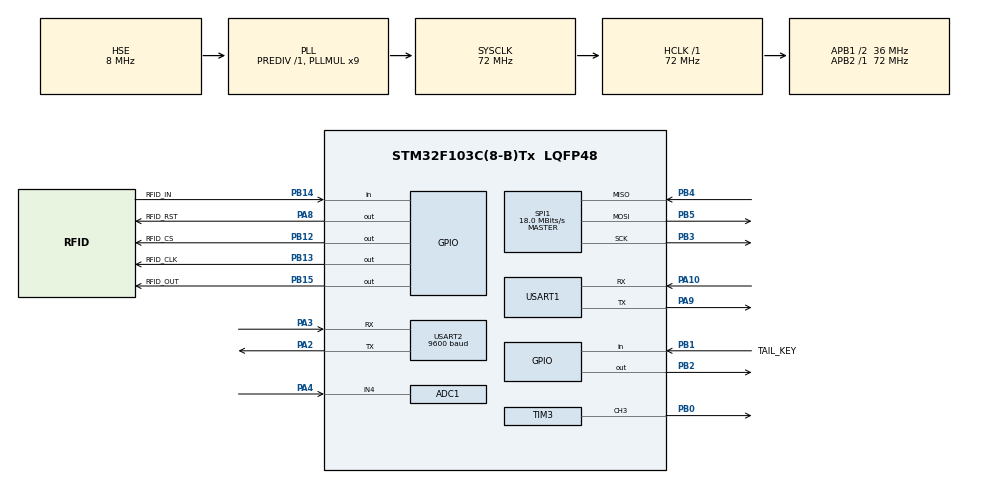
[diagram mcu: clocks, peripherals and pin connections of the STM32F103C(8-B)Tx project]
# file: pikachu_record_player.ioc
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ADC1.Channel-0\#ChannelRegularConversion=ADC_CHANNEL_4
ADC1.ContinuousConvMode=ENABLE
ADC1.NbrOfConversionFlag=1
ADC1.Rank-0\#ChannelRegularConversion=1
ADC1.SamplingTime-0\#ChannelRegularConversion=ADC_SAMPLETIME_239CYCLES_5
ADC1.master=1
Dma.ADC1.4.Direction=DMA_PERIPH_TO_MEMORY
Dma.ADC1.4.Instance=DMA1_Channel1
Dma.ADC1.4.MemDataAlignment=DMA_MDATAALIGN_HALFWORD
Dma.ADC1.4.MemInc=DMA_MINC_ENABLE
Dma.ADC1.4.Mode=DMA_CIRCULAR
Dma.ADC1.4.PeriphDataAlignment=DMA_PDATAALIGN_HALFWORD
Dma.ADC1.4.PeriphInc=DMA_PINC_DISABLE
Dma.ADC1.4.Priority=DMA_PRIORITY_LOW
Dma.Request0=USART1_RX
Dma.Request1=USART1_TX
Dma.Request2=USART2_RX
Dma.Request3=USART2_TX
Dma.Request4=ADC1
Dma.USART1_RX.0.Direction=DMA_PERIPH_TO_MEMORY
Dma.USART1_RX.0.Instance=DMA1_Channel5
Dma.USART1_RX.0.MemDataAlignment=DMA_MDATAALIGN_BYTE
Dma.USART1_RX.0.MemInc=DMA_MINC_ENABLE
Dma.USART1_RX.0.Mode=DMA_NORMAL
Dma.USART1_RX.0.PeriphDataAlignment=DMA_PDATAALIGN_BYTE
Dma.USART1_RX.0.PeriphInc=DMA_PINC_DISABLE
Dma.USART1_RX.0.Priority=DMA_PRIORITY_LOW
Dma.USART1_TX.1.Direction=DMA_MEMORY_TO_PERIPH
Dma.USART1_TX.1.Instance=DMA1_Channel4
Dma.USART1_TX.1.MemDataAlignment=DMA_MDATAALIGN_BYTE
Dma.USART1_TX.1.MemInc=DMA_MINC_ENABLE
Dma.USART1_TX.1.Mode=DMA_NORMAL
Dma.USART1_TX.1.PeriphDataAlignment=DMA_PDATAALIGN_BYTE
Dma.USART1_TX.1.PeriphInc=DMA_PINC_DISABLE
Dma.USART1_TX.1.Priority=DMA_PRIORITY_LOW
Dma.USART2_RX.2.Direction=DMA_PERIPH_TO_MEMORY
Dma.USART2_RX.2.Instance=DMA1_Channel6
Dma.USART2_RX.2.MemDataAlignment=DMA_MDATAALIGN_BYTE
Dma.USART2_RX.2.MemInc=DMA_MINC_ENABLE
Dma.USART2_RX.2.Mode=DMA_NORMAL
Dma.USART2_RX.2.PeriphDataAlignment=DMA_PDATAALIGN_BYTE
Dma.USART2_RX.2.PeriphInc=DMA_PINC_DISABLE
Dma.USART2_RX.2.Priority=DMA_PRIORITY_LOW
Dma.USART2_TX.3.Direction=DMA_MEMORY_TO_PERIPH
Dma.USART2_TX.3.Instance=DMA1_Channel7
Dma.USART2_TX.3.MemDataAlignment=DMA_MDATAALIGN_BYTE
Dma.USART2_TX.3.MemInc=DMA_MINC_ENABLE
Dma.USART2_TX.3.Mode=DMA_NORMAL
Dma.USART2_TX.3.PeriphDataAlignment=DMA_PDATAALIGN_BYTE
Dma.USART2_TX.3.PeriphInc=DMA_PINC_DISABLE
Dma.USART2_TX.3.Priority=DMA_PRIORITY_LOW
FREERTOS.INCLUDE_vTaskDelayUntil=1
FREERTOS.Tasks01=defaultTask,0,128,StartDefaultTask,Default,NULL,Dynamic,NULL,NULL
Mcu.Family=STM32F1
Mcu.Name=STM32F103C(8-B)Tx
Mcu.Package=LQFP48
NVIC.DMA1_Channel1_IRQn=true\:15\:0\:true\:false\:true\:true\:false\:true\:true
NVIC.DMA1_Channel4_IRQn=true\:5\:0\:false\:false\:true\:true\:false\:true\:true
NVIC.DMA1_Channel5_IRQn=true\:5\:0\:false\:false\:true\:true\:false\:true\:true
NVIC.DMA1_Channel6_IRQn=true\:5\:0\:false\:false\:true\:true\:false\:true\:true
NVIC.DMA1_Channel7_IRQn=true\:5\:0\:false\:false\:true\:true\:false\:true\:true
NVIC.PriorityGroup=NVIC_PRIORITYGROUP_4
NVIC.TIM4_IRQn=true\:5\:0\:true\:false\:true\:false\:false\:true\:true
NVIC.TimeBase=TIM4_IRQn
NVIC.TimeBaseIP=TIM4
NVIC.USART1_IRQn=true\:5\:0\:false\:false\:true\:true\:true\:true\:true
NVIC.USART2_IRQn=true\:5\:0\:false\:false\:true\:true\:true\:true\:true
PA10.Mode=Asynchronous
PA10.Signal=USART1_RX
PA13.Mode=Serial_Wire
PA13.Signal=SYS_JTMS-SWDIO
PA14.Mode=Serial_Wire
PA14.Signal=SYS_JTCK-SWCLK
PA2.Mode=Asynchronous
PA2.Signal=USART2_TX
PA3.Mode=Asynchronous
PA3.Signal=USART2_RX
PA4.Signal=ADCx_IN4
PA8.GPIO_Label=RFID_RST
PA8.Signal=GPIO_Output
PA9.Mode=Asynchronous
PA9.Signal=USART1_TX
PB0.Signal=S_TIM3_CH3
PB1.GPIO_Label=TAIL_KEY
PB1.GPIO_PuPd=GPIO_PULLUP
PB1.Signal=GPIO_Input
PB12.GPIO_Label=RFID_CS
PB12.Signal=GPIO_Output
PB13.GPIO_Label=RFID_CLK
PB13.Signal=GPIO_Output
PB14.GPIO_Label=RFID_IN
PB14.Signal=GPIO_Input
PB15.GPIO_Label=RFID_OUT
PB15.Signal=GPIO_Output
PB2.Signal=GPIO_Output
PB3.Mode=Full_Duplex_Master
PB3.Signal=SPI1_SCK
PB4.Mode=Full_Duplex_Master
PB4.Signal=SPI1_MISO
PB5.Mode=Full_Duplex_Master
PB5.Signal=SPI1_MOSI
PD0-OSC_IN.Mode=HSE-External-Oscillator
PD0-OSC_IN.Signal=RCC_OSC_IN
PD1-OSC_OUT.Mode=HSE-External-Oscillator
PD1-OSC_OUT.Signal=RCC_OSC_OUT
ProjectManager.HeapSize=0x200
ProjectManager.StackSize=0x400
ProjectManager.TargetToolchain=MDK-ARM V5.32
RCC.ADCPresc=RCC_ADCPCLK2_DIV6
RCC.AHBFreq_Value=72000000
RCC.APB1CLKDivider=RCC_HCLK_DIV2
RCC.APB1Freq_Value=36000000
RCC.APB1TimFreq_Value=72000000
RCC.APB2Freq_Value=72000000
RCC.APB2TimFreq_Value=72000000
RCC.HCLKFreq_Value=72000000
RCC.PLLMUL=RCC_PLL_MUL9
RCC.PLLSourceVirtual=RCC_PLLSOURCE_HSE
RCC.SYSCLKFreq_VALUE=72000000
RCC.SYSCLKSource=RCC_SYSCLKSOURCE_PLLCLK
RCC.USBFreq_Value=72000000
SH.ADCx_IN4.0=ADC1_IN4,IN4
SH.S_TIM3_CH3.0=TIM3_CH3,PWM Generation3 CH3
SPI1.BaudRatePrescaler=SPI_BAUDRATEPRESCALER_4
SPI1.CalculateBaudRate=18.0 MBits/s
SPI1.Direction=SPI_DIRECTION_2LINES
SPI1.Mode=SPI_MODE_MASTER
SPI1.VirtualType=VM_MASTER
TIM3.Channel-PWM\ Generation3\ CH3=TIM_CHANNEL_3
TIM3.Period=99
TIM3.Prescaler=7199
USART1.VirtualMode=VM_ASYNC
USART2.BaudRate=9600
USART2.VirtualMode=VM_ASYNC
VP_FREERTOS_VS_CMSIS_V1.Mode=CMSIS_V1
VP_SYS_VS_tim4.Mode=TIM4
board=custom

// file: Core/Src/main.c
/* USER CODE BEGIN Header */
/**
  ******************************************************************************
  * @file           : main.c
  * @brief          : Main program body
  ******************************************************************************
  * @attention
  *
  * Copyright (c) 2024 STMicroelectronics.
  * All rights reserved.
  *
  * This software is licensed under terms that can be found in the LICENSE file
  * in the root directory of this software component.
  * If no LICENSE file comes with this software, it is provided AS-IS.
  *
  ******************************************************************************
  */
/* USER CODE END Header */
#include "main.h"
#include "cmsis_os.h"
#include "adc.h"
#include "dma.h"
#include "spi.h"
#include "tim.h"
#include "usart.h"
#include "gpio.h"

void SystemClock_Config(void);
void MX_FREERTOS_Init(void);

int main(void)
{

  /* MCU Configuration--------------------------------------------------------*/

  /* Reset of all peripherals, Initializes the Flash interface and the Systick. */
  HAL_Init();

  /* Configure the system clock */
  SystemClock_Config();

  /* Initialize all configured peripherals */
  MX_GPIO_Init();
  MX_DMA_Init();
  MX_SPI1_Init();
  MX_USART1_UART_Init();
  MX_USART2_UART_Init();
  MX_ADC1_Init();
  MX_TIM3_Init();
  /* USER CODE BEGIN 2 */
	HAL_Delay(2000);
  /* USER CODE END 2 */

  /* Call init function for freertos objects (in freertos.c) */
  MX_FREERTOS_Init();

  /* Start scheduler */
  osKernelStart();

  /* We should never get here as control is now taken by the scheduler */
  /* Infinite loop */
  while (1)
  {

  }
}

void SystemClock_Config(void)
{
  RCC_OscInitTypeDef RCC_OscInitStruct = {0};
  RCC_ClkInitTypeDef RCC_ClkInitStruct = {0};
  RCC_PeriphCLKInitTypeDef PeriphClkInit = {0};

  /** Initializes the RCC Oscillators according to the specified parameters
  * in the RCC_OscInitTypeDef structure.
  */
  RCC_OscInitStruct.OscillatorType = RCC_OSCILLATORTYPE_HSE;
  RCC_OscInitStruct.HSEState = RCC_HSE_ON;
  RCC_OscInitStruct.HSEPredivValue = RCC_HSE_PREDIV_DIV1;
  RCC_OscInitStruct.HSIState = RCC_HSI_ON;
  RCC_OscInitStruct.PLL.PLLState = RCC_PLL_ON;
  RCC_OscInitStruct.PLL.PLLSource = RCC_PLLSOURCE_HSE;
  RCC_OscInitStruct.PLL.PLLMUL = RCC_PLL_MUL9;
  if (HAL_RCC_OscConfig(&RCC_OscInitStruct) != HAL_OK)
  {
    Error_Handler();
  }

  /** Initializes the CPU, AHB and APB buses clocks
  */
  RCC_ClkInitStruct.ClockType = RCC_CLOCKTYPE_HCLK|RCC_CLOCKTYPE_SYSCLK
                              |RCC_CLOCKTYPE_PCLK1|RCC_CLOCKTYPE_PCLK2;
  RCC_ClkInitStruct.SYSCLKSource = RCC_SYSCLKSOURCE_PLLCLK;
  RCC_ClkInitStruct.AHBCLKDivider = RCC_SYSCLK_DIV1;
  RCC_ClkInitStruct.APB1CLKDivider = RCC_HCLK_DIV2;
  RCC_ClkInitStruct.APB2CLKDivider = RCC_HCLK_DIV1;

  if (HAL_RCC_ClockConfig(&RCC_ClkInitStruct, FLASH_LATENCY_2) != HAL_OK)
  {
    Error_Handler();
  }
  PeriphClkInit.PeriphClockSelection = RCC_PERIPHCLK_ADC;
  PeriphClkInit.AdcClockSelection = RCC_ADCPCLK2_DIV6;
  if (HAL_RCCEx_PeriphCLKConfig(&PeriphClkInit) != HAL_OK)
  {
    Error_Handler();
  }
}

void HAL_TIM_PeriodElapsedCallback(TIM_HandleTypeDef *htim)
{
  if (htim->Instance == TIM4) {
    HAL_IncTick();
  }
}

void Error_Handler(void)
{
  __disable_irq();
  while (1)
  {
  }
}

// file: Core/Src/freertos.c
/* USER CODE BEGIN Header */
/**
  ******************************************************************************
  * File Name          : freertos.c
  * Description        : Code for freertos applications
  ******************************************************************************
  * @attention
  *
  * Copyright (c) 2024 STMicroelectronics.
  * All rights reserved.
  *
  * This software is licensed under terms that can be found in the LICENSE file
  * in the root directory of this software component.
  * If no LICENSE file comes with this software, it is provided AS-IS.
  *
  ******************************************************************************
  */
/* USER CODE END Header */

#include "FreeRTOS.h"
#include "task.h"
#include "main.h"
#include "cmsis_os.h"

/* USER CODE BEGIN Includes */
#include "Application/include/sys_init.h"
/* USER CODE END Includes */

osThreadId defaultTaskHandle;

void StartDefaultTask(void const * argument);

void MX_FREERTOS_Init(void); /* (MISRA C 2004 rule 8.1) */

/* GetIdleTaskMemory prototype (linked to static allocation support) */
void vApplicationGetIdleTaskMemory( StaticTask_t **ppxIdleTaskTCBBuffer, StackType_t **ppxIdleTaskStackBuffer, uint32_t *pulIdleTaskStackSize );

/* USER CODE BEGIN GET_IDLE_TASK_MEMORY */
static StaticTask_t xIdleTaskTCBBuffer;
static StackType_t xIdleStack[configMINIMAL_STACK_SIZE];

void vApplicationGetIdleTaskMemory( StaticTask_t **ppxIdleTaskTCBBuffer, StackType_t **ppxIdleTaskStackBuffer, uint32_t *pulIdleTaskStackSize )
{
  *ppxIdleTaskTCBBuffer = &xIdleTaskTCBBuffer;
  *ppxIdleTaskStackBuffer = &xIdleStack[0];
  *pulIdleTaskStackSize = configMINIMAL_STACK_SIZE;
  /* place for user code */
}
/* USER CODE END GET_IDLE_TASK_MEMORY */

void MX_FREERTOS_Init(void) {

  /* Create the thread(s) */
  /* definition and creation of defaultTask */
  osThreadDef(defaultTask, StartDefaultTask, osPriorityNormal, 0, 128);
  defaultTaskHandle = osThreadCreate(osThread(defaultTask), NULL);

}

void StartDefaultTask(void const * argument)
{
  /* USER CODE BEGIN StartDefaultTask */
  SysInit();
	osThreadTerminate (defaultTaskHandle);
  /* Infinite loop */
  for(;;)
  {
    osDelay(1);
  }
  /* USER CODE END StartDefaultTask */
}
